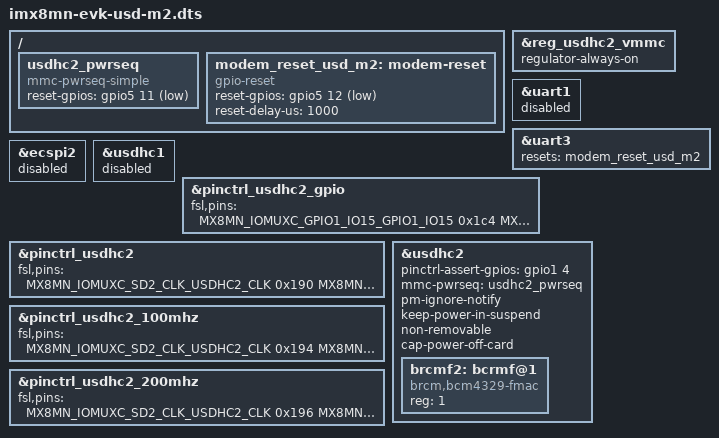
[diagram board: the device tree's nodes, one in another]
// SPDX-License-Identifier: (GPL-2.0+ OR MIT)
/*
 * Copyright 2019 NXP
 */

/dts-v1/;

#include "imx8mn-evk.dts"

/ {
  	usdhc2_pwrseq: usdhc2_pwrseq {
		compatible = "mmc-pwrseq-simple";
		pinctrl-names = "default";
		reset-gpios = <&gpio5 11 GPIO_ACTIVE_LOW>;  /* WL REG ON */
	};

	modem_reset_usd_m2: modem-reset {
		compatible = "gpio-reset";
		reset-gpios = <&gpio5 12 GPIO_ACTIVE_LOW>;  /* BT REG ON */
		reset-delay-us = <1000>;
		#reset-cells = <0>;
	};
};

&reg_usdhc2_vmmc {
  	regulator-always-on;
};

&uart1 {
	/* Onboard AW-CM358SM BT */
	status = "disabled";
};

&uart3 {
  	resets = <&modem_reset_usd_m2>;
};

&ecspi2 {
	status = "disabled";
};

&usdhc1 {
	/* Disable AW-CM358SM */
	status = "disabled";
};


&pinctrl_usdhc2_gpio {
	fsl,pins = <
    		MX8MN_IOMUXC_GPIO1_IO15_GPIO1_IO15	0x1c4
		MX8MN_IOMUXC_ECSPI2_MOSI_GPIO5_IO11	0x19  /* WL_REG_ON */
    		MX8MN_IOMUXC_ECSPI2_MISO_GPIO5_IO12	0x19  /* BT_REG_ON */
    		MX8MN_IOMUXC_GPIO1_IO04_GPIO1_IO4	0x1d0 /* Murata -- should be pull-up on this */
	>;
};

&pinctrl_usdhc2 {
	fsl,pins = <
		MX8MN_IOMUXC_SD2_CLK_USDHC2_CLK		0x190
		MX8MN_IOMUXC_SD2_CMD_USDHC2_CMD		0x1d0
		MX8MN_IOMUXC_SD2_DATA0_USDHC2_DATA0	0x1d0
		MX8MN_IOMUXC_SD2_DATA1_USDHC2_DATA1	0x1d0
		MX8MN_IOMUXC_SD2_DATA2_USDHC2_DATA2	0x1d0
		MX8MN_IOMUXC_SD2_DATA3_USDHC2_DATA3	0x1d0
	>;
};

&pinctrl_usdhc2_100mhz {
	fsl,pins = <
		MX8MN_IOMUXC_SD2_CLK_USDHC2_CLK		0x194
		MX8MN_IOMUXC_SD2_CMD_USDHC2_CMD		0x1d4
		MX8MN_IOMUXC_SD2_DATA0_USDHC2_DATA0	0x1d4
		MX8MN_IOMUXC_SD2_DATA1_USDHC2_DATA1	0x1d4
		MX8MN_IOMUXC_SD2_DATA2_USDHC2_DATA2	0x1d4
		MX8MN_IOMUXC_SD2_DATA3_USDHC2_DATA3	0x1d4
	>;
};

&pinctrl_usdhc2_200mhz {
	fsl,pins = <
		MX8MN_IOMUXC_SD2_CLK_USDHC2_CLK		0x196
		MX8MN_IOMUXC_SD2_CMD_USDHC2_CMD		0x1d6
		MX8MN_IOMUXC_SD2_DATA0_USDHC2_DATA0	0x1d6
		MX8MN_IOMUXC_SD2_DATA1_USDHC2_DATA1	0x1d6
		MX8MN_IOMUXC_SD2_DATA2_USDHC2_DATA2	0x1d6
		MX8MN_IOMUXC_SD2_DATA3_USDHC2_DATA3	0x1d6
	>;
};


&usdhc2 {
	#address-cells = <1>;
	#size-cells = <0>;
	pinctrl-assert-gpios = <&gpio1 4 GPIO_ACTIVE_HIGH>; /* Force 1.8V VIO */
	/delete-property/ cd-gpios;
	mmc-pwrseq = <&usdhc2_pwrseq>;
	pm-ignore-notify;
	keep-power-in-suspend;
	non-removable;
	cap-power-off-card;
	brcmf2: bcrmf@1 {
		reg = <1>;
		compatible = "brcm,bcm4329-fmac";
	};
};
